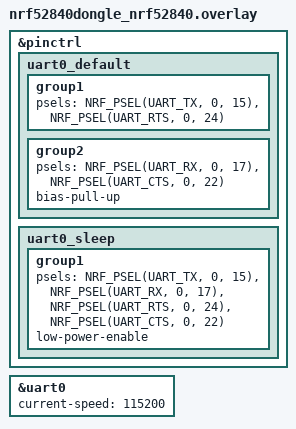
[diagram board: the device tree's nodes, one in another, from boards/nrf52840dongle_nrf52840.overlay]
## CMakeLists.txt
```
#
# Copyright (c) 2018 Nordic Semiconductor
#
# SPDX-License-Identifier: LicenseRef-Nordic-5-Clause
#
cmake_minimum_required(VERSION 3.20.0)

find_package(Zephyr REQUIRED HINTS $ENV{ZEPHYR_BASE})
project(NONE)

FILE(GLOB app_sources src/*.c)
# NORDIC SDK APP START
target_sources(app PRIVATE src/main.c src/uart.c)
# NORDIC SDK APP END
```

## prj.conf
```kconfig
#
# Copyright (c) 2019 Nordic Semiconductor ASA
#
# SPDX-License-Identifier: LicenseRef-Nordic-5-Clause
#
CONFIG_LOG=y
CONFIG_STDOUT_CONSOLE=y
CONFIG_CONSOLE=y 
# New RTT wanted me to do it , now rtt works :)
CONFIG_UART_CONSOLE=n
CONFIG_RTT_CONSOLE=y
CONFIG_USE_SEGGER_RTT=y

CONFIG_NCS_SAMPLES_DEFAULTS=y
CONFIG_ESB=y

#UART config
CONFIG_SERIAL=y
CONFIG_UART_INTERRUPT_DRIVEN=y
```

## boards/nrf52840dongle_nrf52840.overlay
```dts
&pinctrl {
    uart0_default: uart0_default {
        group1 {
            psels = <NRF_PSEL(UART_TX, 0, 15)>,
             <NRF_PSEL(UART_RTS, 0, 24)>;
        };
        group2 {
            psels = <NRF_PSEL(UART_RX, 0, 17)>,
             <NRF_PSEL(UART_CTS, 0, 22)>;
            bias-pull-up;
        };
    };

    uart0_sleep: uart0_sleep {
		group1 {
			psels = <NRF_PSEL(UART_TX, 0, 15)>,
				<NRF_PSEL(UART_RX, 0, 17)>,
				<NRF_PSEL(UART_RTS, 0, 24)>,
				<NRF_PSEL(UART_CTS, 0, 22)>;
			low-power-enable;
		};
	};
};
&uart0 {
    current-speed = <115200>;
};
```

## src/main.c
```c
/*
 * Copyright (c) 2018 Nordic Semiconductor ASA
 *
 * SPDX-License-Identifier: LicenseRef-Nordic-5-Clause
 */
#include <zephyr/device.h>
#include <zephyr/devicetree.h>
#include <zephyr/drivers/clock_control.h>
#include <zephyr/drivers/clock_control/nrf_clock_control.h>
#include <zephyr/drivers/gpio.h>
#include <zephyr/irq.h>
#include <zephyr/logging/log.h>
#include <nrf.h>
#include <esb.h>
#include <zephyr/kernel.h>
#include <zephyr/types.h>

#include "uart.h"


LOG_MODULE_REGISTER(esb_prx, CONFIG_ESB_PRX_APP_LOG_LEVEL);

static const struct gpio_dt_spec leds[] = {
	GPIO_DT_SPEC_GET(DT_ALIAS(led0), gpios),
	GPIO_DT_SPEC_GET(DT_ALIAS(led1), gpios),
	GPIO_DT_SPEC_GET(DT_ALIAS(led2), gpios),
	GPIO_DT_SPEC_GET(DT_ALIAS(led3), gpios),
};

/*BUILD_ASSERT(DT_SAME_NODE(DT_GPIO_CTLR(DT_ALIAS(led0), gpios),
			  DT_GPIO_CTLR(DT_ALIAS(led1), gpios)) &&
	     DT_SAME_NODE(DT_GPIO_CTLR(DT_ALIAS(led0), gpios),
			  DT_GPIO_CTLR(DT_ALIAS(led2), gpios)) &&
	     DT_SAME_NODE(DT_GPIO_CTLR(DT_ALIAS(led0), gpios),
			  DT_GPIO_CTLR(DT_ALIAS(led3), gpios)),
	     "All LEDs must be on the same port");*/

static struct esb_payload rx_payload;
static struct esb_payload tx_payload = ESB_CREATE_PAYLOAD(0,
	0x10, 0x11, 0x12, 0x13, 0x14, 0x15, 0x16, 0x17);

static int leds_init(void)
{
	if (!device_is_ready(leds[0].port)) {
		LOG_ERR("LEDs port not ready");
		return -ENODEV;
	}

	for (size_t i = 0; i < ARRAY_SIZE(leds); i++) {
		int err = gpio_pin_configure_dt(&leds[i], GPIO_OUTPUT);

		if (err) {
			LOG_ERR("Unable to configure LED%u, err %d.", i, err);
			return err;
		}
	}

	return 0;
}

static void leds_update(uint8_t value)
{
	bool led0_status = !(value % 8 > 0 && value % 8 <= 4);
	bool led1_status = !(value % 8 > 1 && value % 8 <= 5);
	bool led2_status = !(value % 8 > 2 && value % 8 <= 6);
	bool led3_status = !(value % 8 > 3);

	gpio_port_pins_t mask = BIT(leds[0].pin) | BIT(leds[1].pin) |
				BIT(leds[2].pin) | BIT(leds[3].pin);

	gpio_port_value_t val = led0_status << leds[0].pin |
				led1_status << leds[1].pin |
				led2_status << leds[2].pin |
				led3_status << leds[3].pin;

	gpio_port_set_masked_raw(leds[0].port, mask, val);
}

void event_handler(struct esb_evt const *event)
{
	switch (event->evt_id) {
	case ESB_EVENT_TX_SUCCESS:
		LOG_DBG("TX SUCCESS EVENT");
		break;
	case ESB_EVENT_TX_FAILED:
		LOG_DBG("TX FAILED EVENT");
		break;
	case ESB_EVENT_RX_RECEIVED:
		if (esb_read_rx_payload(&rx_payload) == 0) { // TODO send the number of bytes received
			LOG_DBG("Packet received, len %d : "
				"0x%02x, 0x%02x, 0x%02x, 0x%02x, "
				"0x%02x, 0x%02x, 0x%02x, 0x%02x",
				rx_payload.length, rx_payload.data[0],
				rx_payload.data[1], rx_payload.data[2],
				rx_payload.data[3], rx_payload.data[4],
				rx_payload.data[5], rx_payload.data[6],
				rx_payload.data[7]);
			leds_update(rx_payload.data[1]);
			if ((rx_payload.data[0] & 0xf3) == 0x30){
				uart_queue_send(&rx_payload);
			}
			// uart_queue_send(&rx_payload);
		} else {
			LOG_ERR("Error while reading rx packet");
		}
		break;
	}
}

int clocks_start(void)
{
	int err;
	int res;
	struct onoff_manager *clk_mgr;
	struct onoff_client clk_cli;

	clk_mgr = z_nrf_clock_control_get_onoff(CLOCK_CONTROL_NRF_SUBSYS_HF);
	if (!clk_mgr) {
		LOG_ERR("Unable to get the Clock manager");
		return -ENXIO;
	}

	sys_notify_init_spinwait(&clk_cli.notify);

	err = onoff_request(clk_mgr, &clk_cli);
	if (err < 0) {
		LOG_ERR("Clock request failed: %d", err);
		return err;
	}

	do {
		err = sys_notify_fetch_result(&clk_cli.notify, &res);
		if (!err && res) {
			LOG_ERR("Clock could not be started: %d", res);
			return res;
		}
	} while (err);

	LOG_DBG("HF clock started");
	return 0;
}

int esb_initialize(void)
{
	int err;
	/* These are arbitrary default addresses. In end user products
	 * different addresses should be used for each set of devices.
	 */
	uint8_t base_addr_1[4] = {0xE6, 0xE6, 0xE6, 0xE6};
	uint8_t base_addr_0[4] = {0xC2, 0xC2, 0xC2, 0xC2};
	uint8_t addr_prefix[8] = {0xE7, 0x00, 0x00, 0x00, 0x00, 0x00, 0x00, 0x00};
//{0x00,0x00,0x00,0xFF};//
	struct esb_config config = ESB_DEFAULT_CONFIG;
	config.protocol = ESB_PROTOCOL_ESB_DPL;
	config.bitrate = ESB_BITRATE_2MBPS;
	config.mode = ESB_MODE_PRX;
	config.event_handler = event_handler;
	config.selective_auto_ack = true;
	
	err = esb_init(&config);
	if (err) {
		return err;
	}
	nrf_radio_txaddress_set(NRF_RADIO, 0);
    nrf_radio_rxaddresses_set(NRF_RADIO, 0x03u);

	// Configure CRC
    nrf_radio_crc_configure(NRF_RADIO, 2, NRF_RADIO_CRC_ADDR_INCLUDE, 0x11021UL);
    nrf_radio_crcinit_set(NRF_RADIO, 0xfffful);

	err = esb_set_rf_channel(80);
	if (err) {
		return err;
	}
	err = esb_set_base_address_0(base_addr_0);
	if (err) {
		return err;
	}

	err = esb_set_base_address_1(base_addr_1);
	if (err) {
		return err;
	}

	err = esb_set_prefixes(addr_prefix, ARRAY_SIZE(addr_prefix));
	if (err) {
		return err;
	}

	return 0;
}

int main(void)
{
	int err;

	LOG_INF("Enhanced ShockBurst prx sample");

	err = clocks_start();
	if (err) {
		return 0;
	}

	err = leds_init();
	if (err) {
		return 0;
	}

	err = esb_initialize();
	if (err) {
		LOG_ERR("ESB initialization failed, err %d", err);
		return 0;
	}

	LOG_INF("Initialization complete");

	err = esb_write_payload(&tx_payload);
	if (err) {
		LOG_ERR("Write payload, err %d", err);
		return 0;
	}

	LOG_INF("Setting up for packet receiption");

	err = esb_start_rx();
	if (err) {
		LOG_ERR("RX setup failed, err %d", err);
		return 0;
	}
	uart_initialization();
	struct esb_payload command = {0};
	print_uart("UART Initialized");
	while (1) {
		if (uart_queue_receive(&command) == 0){
			LOG_DBG("UART Message:%s",(char*)command.data);
			//print_uart("Echo: ");
			print_uart_payload(command.data,command.length);
			//print_uart("\r\n");
		}
		

	}

	/* return to idle thread */
	LOG_DBG("MAIN End");
	return 0;
}
```

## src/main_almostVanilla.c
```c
/*
 * Copyright (c) 2018 Nordic Semiconductor ASA
 *
 * SPDX-License-Identifier: LicenseRef-Nordic-5-Clause
 */
#include <zephyr/device.h>
#include <zephyr/devicetree.h>
#include <zephyr/drivers/clock_control.h>
#include <zephyr/drivers/clock_control/nrf_clock_control.h>
#include <zephyr/drivers/gpio.h>
#include <zephyr/irq.h>
#include <zephyr/logging/log.h>
#include <nrf.h>
#include <esb.h>
#include <zephyr/kernel.h>
#include <zephyr/types.h>

LOG_MODULE_REGISTER(esb_prx, CONFIG_ESB_PRX_APP_LOG_LEVEL);

static const struct gpio_dt_spec leds[] = {
	GPIO_DT_SPEC_GET(DT_ALIAS(led0), gpios),
	GPIO_DT_SPEC_GET(DT_ALIAS(led1), gpios),
	GPIO_DT_SPEC_GET(DT_ALIAS(led2), gpios),
	GPIO_DT_SPEC_GET(DT_ALIAS(led3), gpios),
};

/*BUILD_ASSERT(DT_SAME_NODE(DT_GPIO_CTLR(DT_ALIAS(led0), gpios),
			  DT_GPIO_CTLR(DT_ALIAS(led1), gpios)) &&
	     DT_SAME_NODE(DT_GPIO_CTLR(DT_ALIAS(led0), gpios),
			  DT_GPIO_CTLR(DT_ALIAS(led2), gpios)) &&
	     DT_SAME_NODE(DT_GPIO_CTLR(DT_ALIAS(led0), gpios),
			  DT_GPIO_CTLR(DT_ALIAS(led3), gpios)),
	     "All LEDs must be on the same port");*/

static struct esb_payload rx_payload;
static struct esb_payload tx_payload = ESB_CREATE_PAYLOAD(0,
	0x10, 0x11, 0x12, 0x13, 0x14, 0x15, 0x16, 0x17);

static int leds_init(void)
{
	if (!device_is_ready(leds[0].port)) {
		LOG_ERR("LEDs port not ready");
		return -ENODEV;
	}

	for (size_t i = 0; i < ARRAY_SIZE(leds); i++) {
		int err = gpio_pin_configure_dt(&leds[i], GPIO_OUTPUT);

		if (err) {
			LOG_ERR("Unable to configure LED%u, err %d.", i, err);
			return err;
		}
	}

	return 0;
}

static void leds_update(uint8_t value)
{
	bool led0_status = !(value % 8 > 0 && value % 8 <= 4);
	bool led1_status = !(value % 8 > 1 && value % 8 <= 5);
	bool led2_status = !(value % 8 > 2 && value % 8 <= 6);
	bool led3_status = !(value % 8 > 3);

	gpio_port_pins_t mask = BIT(leds[0].pin) | BIT(leds[1].pin) |
				BIT(leds[2].pin) | BIT(leds[3].pin);

	gpio_port_value_t val = led0_status << leds[0].pin |
				led1_status << leds[1].pin |
				led2_status << leds[2].pin |
				led3_status << leds[3].pin;

	gpio_port_set_masked_raw(leds[0].port, mask, val);
}

void event_handler(struct esb_evt const *event)
{
	switch (event->evt_id) {
	case ESB_EVENT_TX_SUCCESS:
		LOG_DBG("TX SUCCESS EVENT");
		break;
	case ESB_EVENT_TX_FAILED:
		LOG_DBG("TX FAILED EVENT");
		break;
	case ESB_EVENT_RX_RECEIVED:
		if (esb_read_rx_payload(&rx_payload) == 0) {
			LOG_DBG("Packet received, len %d : "
				"0x%02x, 0x%02x, 0x%02x, 0x%02x, "
				"0x%02x, 0x%02x, 0x%02x, 0x%02x",
				rx_payload.length, rx_payload.data[0],
				rx_payload.data[1], rx_payload.data[2],
				rx_payload.data[3], rx_payload.data[4],
				rx_payload.data[5], rx_payload.data[6],
				rx_payload.data[7]);

			leds_update(rx_payload.data[1]);
		} else {
			LOG_ERR("Error while reading rx packet");
		}
		break;
	}
}

int clocks_start(void)
{
	int err;
	int res;
	struct onoff_manager *clk_mgr;
	struct onoff_client clk_cli;

	clk_mgr = z_nrf_clock_control_get_onoff(CLOCK_CONTROL_NRF_SUBSYS_HF);
	if (!clk_mgr) {
		LOG_ERR("Unable to get the Clock manager");
		return -ENXIO;
	}

	sys_notify_init_spinwait(&clk_cli.notify);

	err = onoff_request(clk_mgr, &clk_cli);
	if (err < 0) {
		LOG_ERR("Clock request failed: %d", err);
		return err;
	}

	do {
		err = sys_notify_fetch_result(&clk_cli.notify, &res);
		if (!err && res) {
			LOG_ERR("Clock could not be started: %d", res);
			return res;
		}
	} while (err);

	LOG_DBG("HF clock started");
	return 0;
}

int esb_initialize(void)
{
	int err;
	/* These are arbitrary default addresses. In end user products
	 * different addresses should be used for each set of devices.
	 */
	uint8_t base_addr_0[4] = {0xE7, 0xE7, 0xE7, 0xE7};
	uint8_t base_addr_1[4] = {0xC2, 0xC2, 0xC2, 0xC2};
	uint8_t addr_prefix[8] = {0xFF, 0x00, 0x00, 0x00, 0x00, 0x00, 0x00, 0x00};
//{0x00,0x00,0x00,0xFF};//
	struct esb_config config = ESB_DEFAULT_CONFIG;
	config.protocol = ESB_PROTOCOL_ESB_DPL;
	config.bitrate = ESB_BITRATE_2MBPS;
	config.mode = ESB_MODE_PRX;
	config.event_handler = event_handler;
	config.selective_auto_ack = true;
	
	err = esb_init(&config);
	if (err) {
		return err;
	}
	nrf_radio_txaddress_set(NRF_RADIO, 0);
    nrf_radio_rxaddresses_set(NRF_RADIO, 0x03u);

	// Configure CRC
    nrf_radio_crc_configure(NRF_RADIO, 2, NRF_RADIO_CRC_ADDR_INCLUDE, 0x11021UL);
    nrf_radio_crcinit_set(NRF_RADIO, 0xfffful);

	err = esb_set_rf_channel(80);
	if (err) {
		return err;
	}
	err = esb_set_base_address_0(base_addr_0);
	if (err) {
		return err;
	}

	err = esb_set_base_address_1(base_addr_1);
	if (err) {
		return err;
	}

	err = esb_set_prefixes(addr_prefix, ARRAY_SIZE(addr_prefix));
	if (err) {
		return err;
	}

	return 0;
}

int main(void)
{
	int err;

	LOG_INF("Enhanced ShockBurst prx sample");

	err = clocks_start();
	if (err) {
		return 0;
	}

	err = leds_init();
	if (err) {
		return 0;
	}

	err = esb_initialize();
	if (err) {
		LOG_ERR("ESB initialization failed, err %d", err);
		return 0;
	}

	LOG_INF("Initialization complete");

	err = esb_write_payload(&tx_payload);
	if (err) {
		LOG_ERR("Write payload, err %d", err);
		return 0;
	}

	LOG_INF("Setting up for packet receiption");

	err = esb_start_rx();
	if (err) {
		LOG_ERR("RX setup failed, err %d", err);
		return 0;
	}

	/* return to idle thread */
	return 0;
}
```

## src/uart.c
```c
#include "uart.h"

K_MSGQ_DEFINE(command_queue, sizeof(struct esb_payload), 10, 4);
LOG_MODULE_REGISTER(uart,4);


void print_uart(char *buf)
{
	int msg_len = strlen(buf);

	for (int i = 0; i < msg_len; i++) {
		uart_poll_out(uart_dev, buf[i]);
	}
}

void print_uart_payload(uint8_t *buf, uint16_t msg_len){
    uart_poll_out(uart_dev,msg_len);
    for (int i = 0; i < msg_len; i++) {
		uart_poll_out(uart_dev, buf[i]);
	}
}
uart_msg_t msg = new_msg;
static uint8_t bytes_to_read = 0;
static uint8_t rx_buf[32];
static uint8_t rx_buf_pos = 0;

void serial_cb(const struct device *dev, void *user_data)
{
	uint8_t c;
	

	if (!uart_irq_update(dev)) {
		return;
	}

	if (!uart_irq_rx_ready(dev)) {
		return;
	}

    uart_fifo_read(dev, &c, 1);
    LOG_DBG("byte read: %c",c);
    switch (msg) {
    case new_msg:
        bytes_to_read = c ; // TODO: change back to hex read instead of char 
        msg= current_msg;
        break;
    
    case current_msg:
        rx_buf[rx_buf_pos++] = c;
        if (rx_buf_pos>=bytes_to_read-1){
            rx_buf[rx_buf_pos] = '\0';
            static struct esb_payload command;
            memcpy(command.data, rx_buf, sizeof(uint8_t)*(bytes_to_read));
            LOG_DBG("%s",(char*) command.data);
            LOG_DBG("\r\n");
            command.length = bytes_to_read-1;
            k_msgq_put(&command_queue, &command, K_NO_WAIT); //TODO If in other wait modes, doesnt continue
            bytes_to_read = 0;
            msg = new_msg;
            rx_buf_pos=0;

        }

        break;
    default:
        break;
    }
}

int uart_initialization(){
    if (!device_is_ready(uart_dev)) {
            LOG_DBG("UART device not found!");
            return 1;
        }

    uint8_t err = uart_irq_callback_user_data_set(uart_dev, serial_cb, NULL);
	uart_irq_rx_enable(uart_dev);
    return err;
}

// ****************** Public API *****************

int uart_queue_send(const struct esb_payload *command) {
	return k_msgq_put(&command_queue, command, K_NO_WAIT);
}

int  uart_queue_receive(struct esb_payload *command) {
	return k_msgq_get(&command_queue, command, K_NO_WAIT);
}
```

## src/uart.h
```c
#pragma once
#include <zephyr/kernel.h>

#include <zephyr/device.h>
#include <zephyr/drivers/uart.h>
#include <string.h>
#include <zephyr/drivers/gpio.h>
#include <esb.h>
#include <zephyr/logging/log.h>

#define UART_DEVICE_NODE DT_CHOSEN(zephyr_shell_uart)
static const struct device *const uart_dev = DEVICE_DT_GET(DT_NODELABEL(uart0)); 
//static const struct device *const uart_sys = DEVICE_DT_GET(DT_NODELABEL(uart1)); 
//https://docs.zephyrproject.org/latest/kernel/drivers/index.html#c.DEVICE_DT_GET

struct usb_command {
    char payload[64];
    uint32_t length;
};

typedef enum  {
    new_msg,
    current_msg,
} uart_msg_t;
 
 
//K_MSGQ_DEFINE(command_queue, sizeof(struct usb_command), 10, 4);
#define MSG_SIZE 64
//static char rx_buf[MSG_SIZE];

//K_MSGQ_DEFINE(uart_msgq, MSG_SIZE, 10, 4);

void print_uart(char *buf);
void print_uart_payload(uint8_t *buf, uint16_t msg_len);

void serial_cb(const struct device *dev, void *user_data);
int uart_initialization();


int uart_queue_send(const struct esb_payload *command);

int uart_queue_receive( struct esb_payload *command);
```
